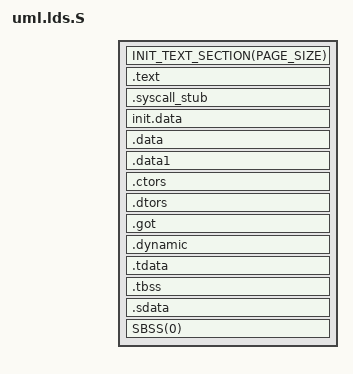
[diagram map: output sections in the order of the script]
/* Copyright Statement:
 *
 * This software/firmware and related documentation ("MediaTek Software") are
 * protected under relevant copyright laws. The information contained herein
 * is confidential and proprietary to MediaTek Inc. and/or its licensors.
 * Without the prior written permission of MediaTek inc. and/or its licensors,
 * any reproduction, modification, use or disclosure of MediaTek Software,
 * and information contained herein, in whole or in part, shall be strictly prohibited.
 *
 * MediaTek Inc. (C) 2010. All rights reserved.
 *
 * BY OPENING THIS FILE, RECEIVER HEREBY UNEQUIVOCALLY ACKNOWLEDGES AND AGREES
 * THAT THE SOFTWARE/FIRMWARE AND ITS DOCUMENTATIONS ("MEDIATEK SOFTWARE")
 * RECEIVED FROM MEDIATEK AND/OR ITS REPRESENTATIVES ARE PROVIDED TO RECEIVER ON
 * AN "AS-IS" BASIS ONLY. MEDIATEK EXPRESSLY DISCLAIMS ANY AND ALL WARRANTIES,
 * EXPRESS OR IMPLIED, INCLUDING BUT NOT LIMITED TO THE IMPLIED WARRANTIES OF
 * MERCHANTABILITY, FITNESS FOR A PARTICULAR PURPOSE OR NONINFRINGEMENT.
 * NEITHER DOES MEDIATEK PROVIDE ANY WARRANTY WHATSOEVER WITH RESPECT TO THE
 * SOFTWARE OF ANY THIRD PARTY WHICH MAY BE USED BY, INCORPORATED IN, OR
 * SUPPLIED WITH THE MEDIATEK SOFTWARE, AND RECEIVER AGREES TO LOOK ONLY TO SUCH
 * THIRD PARTY FOR ANY WARRANTY CLAIM RELATING THERETO. RECEIVER EXPRESSLY ACKNOWLEDGES
 * THAT IT IS RECEIVER'S SOLE RESPONSIBILITY TO OBTAIN FROM ANY THIRD PARTY ALL PROPER LICENSES
 * CONTAINED IN MEDIATEK SOFTWARE. MEDIATEK SHALL ALSO NOT BE RESPONSIBLE FOR ANY MEDIATEK
 * SOFTWARE RELEASES MADE TO RECEIVER'S SPECIFICATION OR TO CONFORM TO A PARTICULAR
 * STANDARD OR OPEN FORUM. RECEIVER'S SOLE AND EXCLUSIVE REMEDY AND MEDIATEK'S ENTIRE AND
 * CUMULATIVE LIABILITY WITH RESPECT TO THE MEDIATEK SOFTWARE RELEASED HEREUNDER WILL BE,
 * AT MEDIATEK'S OPTION, TO REVISE OR REPLACE THE MEDIATEK SOFTWARE AT ISSUE,
 * OR REFUND ANY SOFTWARE LICENSE FEES OR SERVICE CHARGE PAID BY RECEIVER TO
 * MEDIATEK FOR SUCH MEDIATEK SOFTWARE AT ISSUE.
 */

#include <asm-generic/vmlinux.lds.h>
#include <asm/page.h>

OUTPUT_FORMAT(ELF_FORMAT)
OUTPUT_ARCH(ELF_ARCH)
ENTRY(_start)
jiffies = jiffies_64;

SECTIONS
{
  /* This must contain the right address - not quite the default ELF one.*/
  PROVIDE (__executable_start = START);
  /* Static binaries stick stuff here, like the sigreturn trampoline,
   * invisibly to objdump.  So, just make __binary_start equal to the very
   * beginning of the executable, and if there are unmapped pages after this,
   * they are forever unusable.
   */
  __binary_start = START;

  . = START + SIZEOF_HEADERS;

  _text = .;
  _stext = .;
  __init_begin = .;
  INIT_TEXT_SECTION(PAGE_SIZE)
  . = ALIGN(PAGE_SIZE);

  .text      :
  {
    TEXT_TEXT
    SCHED_TEXT
    LOCK_TEXT
    *(.fixup)
    /* .gnu.warning sections are handled specially by elf32.em.  */
    *(.gnu.warning)
    *(.gnu.linkonce.t*)
  }

  . = ALIGN(PAGE_SIZE);
  .syscall_stub : {
	__syscall_stub_start = .;
	*(.__syscall_stub*)
	__syscall_stub_end = .;
  }

  #include "asm/common.lds.S"

  init.data : { INIT_DATA }
  .data    :
  {
    INIT_TASK_DATA(KERNEL_STACK_SIZE)
    . = ALIGN(KERNEL_STACK_SIZE);
    *(.data..init_irqstack)
    DATA_DATA
    *(.gnu.linkonce.d*)
    CONSTRUCTORS
  }
  .data1   : { *(.data1) }
  .ctors         :
  {
    *(.ctors)
  }
  .dtors         :
  {
    *(.dtors)
  }

  .got           : { *(.got.plt) *(.got) }
  .dynamic       : { *(.dynamic) }
  .tdata	  : { *(.tdata .tdata.* .gnu.linkonce.td.*) }
  .tbss		  : { *(.tbss .tbss.* .gnu.linkonce.tb.*) *(.tcommon) }
  /* We want the small data sections together, so single-instruction offsets
     can access them all, and initialized data all before uninitialized, so
     we can shorten the on-disk segment size.  */
  .sdata     : { *(.sdata) }
  _edata  =  .;
  PROVIDE (edata = .);
  . = ALIGN(PAGE_SIZE);
  __bss_start = .;
  PROVIDE(_bss_start = .);
  SBSS(0)
  BSS(0)
  _end = .;
  PROVIDE (end = .);

  STABS_DEBUG

  DWARF_DEBUG

  DISCARDS
}
